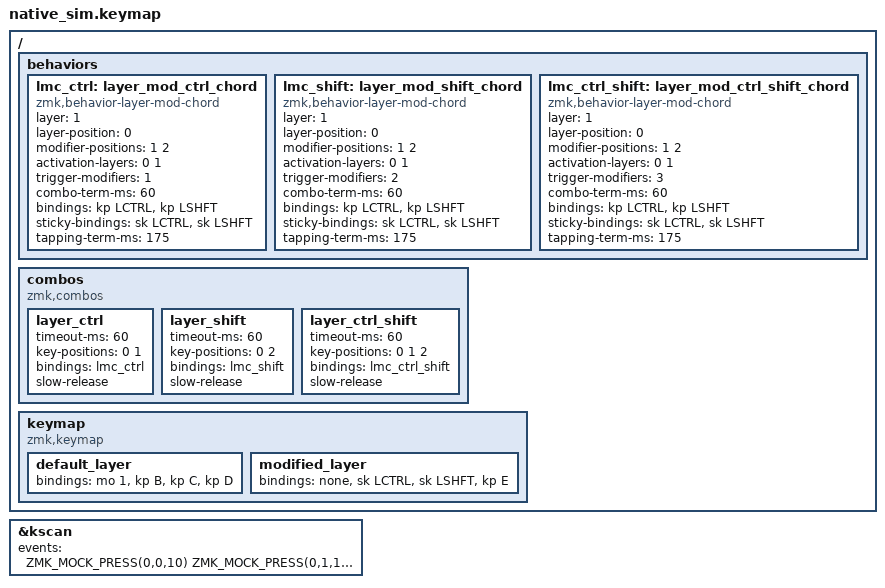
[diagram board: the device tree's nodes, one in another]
#include <behaviors.dtsi>
#include <dt-bindings/zmk/keys.h>
#include <dt-bindings/zmk/kscan_mock.h>

/ {
    behaviors {
        lmc_ctrl: layer_mod_ctrl_chord {
            compatible = "zmk,behavior-layer-mod-chord";
            #binding-cells = <0>;
            layer = <1>;
            layer-position = <0>;
            modifier-positions = <1 2>;
            activation-layers = <0 1>;
            trigger-modifiers = <1>;
            combo-term-ms = <60>;
            bindings = <&kp LCTRL>, <&kp LSHFT>;
            sticky-bindings = <&sk LCTRL>, <&sk LSHFT>;
            tapping-term-ms = <175>;
        };

        lmc_shift: layer_mod_shift_chord {
            compatible = "zmk,behavior-layer-mod-chord";
            #binding-cells = <0>;
            layer = <1>;
            layer-position = <0>;
            modifier-positions = <1 2>;
            activation-layers = <0 1>;
            trigger-modifiers = <2>;
            combo-term-ms = <60>;
            bindings = <&kp LCTRL>, <&kp LSHFT>;
            sticky-bindings = <&sk LCTRL>, <&sk LSHFT>;
            tapping-term-ms = <175>;
        };

        lmc_ctrl_shift: layer_mod_ctrl_shift_chord {
            compatible = "zmk,behavior-layer-mod-chord";
            #binding-cells = <0>;
            layer = <1>;
            layer-position = <0>;
            modifier-positions = <1 2>;
            activation-layers = <0 1>;
            trigger-modifiers = <3>;
            combo-term-ms = <60>;
            bindings = <&kp LCTRL>, <&kp LSHFT>;
            sticky-bindings = <&sk LCTRL>, <&sk LSHFT>;
            tapping-term-ms = <175>;
        };
    };

    combos {
        compatible = "zmk,combos";
        layer_ctrl {
            timeout-ms = <60>;
            key-positions = <0 1>;
            bindings = <&lmc_ctrl>;
            slow-release;
        };
        layer_shift {
            timeout-ms = <60>;
            key-positions = <0 2>;
            bindings = <&lmc_shift>;
            slow-release;
        };
        layer_ctrl_shift {
            timeout-ms = <60>;
            key-positions = <0 1 2>;
            bindings = <&lmc_ctrl_shift>;
            slow-release;
        };
    };

    keymap {
        compatible = "zmk,keymap";

        default_layer {
            bindings = <&mo 1 &kp B &kp C &kp D>;
        };

        modified_layer {
            bindings = <&none &sk LCTRL &sk LSHFT &kp E>;
        };
    };
};

&kscan {
    events = <
        ZMK_MOCK_PRESS(0,0,10)
        ZMK_MOCK_PRESS(0,1,10)
        ZMK_MOCK_PRESS(1,1,10)
        ZMK_MOCK_RELEASE(1,1,10)
        ZMK_MOCK_RELEASE(0,1,10)
        ZMK_MOCK_RELEASE(0,0,10)

        ZMK_MOCK_PRESS(0,1,10)
        ZMK_MOCK_PRESS(0,0,10)
        ZMK_MOCK_PRESS(1,1,10)
        ZMK_MOCK_RELEASE(1,1,10)
        ZMK_MOCK_RELEASE(0,0,10)
        ZMK_MOCK_RELEASE(0,1,10)

        ZMK_MOCK_PRESS(0,1,10)
        ZMK_MOCK_PRESS(1,0,10)
        ZMK_MOCK_PRESS(0,0,10)
        ZMK_MOCK_PRESS(1,1,10)
        ZMK_MOCK_RELEASE(1,1,10)
        ZMK_MOCK_RELEASE(0,0,10)
        ZMK_MOCK_RELEASE(1,0,10)
        ZMK_MOCK_RELEASE(0,1,10)

        ZMK_MOCK_PRESS(0,0,10)
        ZMK_MOCK_PRESS(0,1,10)
        ZMK_MOCK_PRESS(1,0,10)
        ZMK_MOCK_PRESS(1,1,10)
        ZMK_MOCK_RELEASE(1,1,10)
        ZMK_MOCK_RELEASE(1,0,10)
        ZMK_MOCK_RELEASE(0,1,10)
        ZMK_MOCK_RELEASE(0,0,10)

        ZMK_MOCK_PRESS(0,0,10)
        ZMK_MOCK_PRESS(0,1,10)
        ZMK_MOCK_RELEASE(0,0,10)
        ZMK_MOCK_PRESS(1,1,200)
        ZMK_MOCK_RELEASE(1,1,10)
        ZMK_MOCK_RELEASE(0,1,10)

        ZMK_MOCK_PRESS(0,0,10)
        ZMK_MOCK_PRESS(1,0,10)
        ZMK_MOCK_RELEASE(1,0,10)
        ZMK_MOCK_RELEASE(0,0,10)
        ZMK_MOCK_PRESS(1,1,10)
        ZMK_MOCK_RELEASE(1,1,10)

        ZMK_MOCK_PRESS(0,0,10)
        ZMK_MOCK_PRESS(0,1,10)
        ZMK_MOCK_PRESS(1,0,10)
        ZMK_MOCK_RELEASE(0,0,10)
        ZMK_MOCK_RELEASE(0,1,10)
        ZMK_MOCK_RELEASE(1,0,10)
        ZMK_MOCK_PRESS(1,1,10)
        ZMK_MOCK_RELEASE(1,1,10)

        ZMK_MOCK_PRESS(0,1,10)
        ZMK_MOCK_PRESS(0,0,10)
        ZMK_MOCK_RELEASE(0,1,10)
        ZMK_MOCK_RELEASE(0,0,10)
        ZMK_MOCK_PRESS(1,1,10)
        ZMK_MOCK_RELEASE(1,1,10)

        ZMK_MOCK_PRESS(0,1,10)
        ZMK_MOCK_PRESS(1,0,10)
        ZMK_MOCK_PRESS(0,0,10)
        ZMK_MOCK_RELEASE(0,1,10)
        ZMK_MOCK_RELEASE(1,0,10)
        ZMK_MOCK_RELEASE(0,0,10)
        ZMK_MOCK_PRESS(1,1,10)
        ZMK_MOCK_RELEASE(1,1,10)
    >;
};
